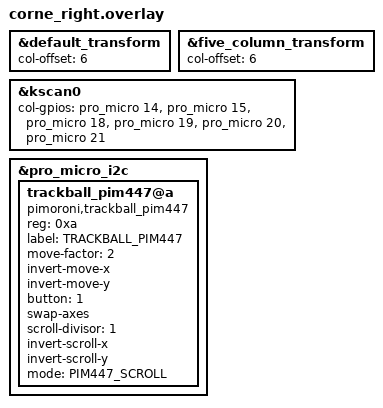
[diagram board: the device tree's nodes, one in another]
/*
 * Copyright (c) 2020 Pete Johanson
 *
 * SPDX-License-Identifier: MIT
 */

#include "corne.dtsi"
#include <dt-bindings/zmk/matrix_transform.h>
#include <dt-bindings/zmk/trackball_pim447.h>

&default_transform {
    col-offset = <6>;
};

&five_column_transform {
    col-offset = <6>;
};

&kscan0 {
    col-gpios
        = <&pro_micro 14 GPIO_ACTIVE_HIGH>
        , <&pro_micro 15 GPIO_ACTIVE_HIGH>
        , <&pro_micro 18 GPIO_ACTIVE_HIGH>
        , <&pro_micro 19 GPIO_ACTIVE_HIGH>
        , <&pro_micro 20 GPIO_ACTIVE_HIGH>
        , <&pro_micro 21 GPIO_ACTIVE_HIGH>
        ;
};

&pro_micro_i2c {
    status = "okay";
    
    trackball_pim447@a {
	    compatible = "pimoroni,trackball_pim447";
	    reg = <0xa>;
	    label = "TRACKBALL_PIM447";
            move-factor = <2>;  // 포인터 속도 증가 (기본값: 1)
            invert-move-x;  // X 축 반전
            invert-move-y;  // Y 축 반전
            button = <1>;  // 볼을 눌렀을 때 오른쪽 클릭 전송
            swap-axes;  // X 및 Y 축 교환
            scroll-divisor = <1>;  // 휠 속도 증가 (기본값: 2)
            invert-scroll-x;  // 휠 X 축 반전
            invert-scroll-y;  // 휠 Y 축 반전
            mode = <PIM447_SCROLL>; // 시작 시 마우스 휠로 작동
      };
};
